# flc_reva_me14 register map
Registers are access not given, no defined reset value unless marked. A register's access mark holds for its fields unless they carry their own. Offsets are from the block's base; lines under a group give offsets from that group; [hi:lo] are bit positions; {n}, {i} and the like mark numbered series; 'fields as' and 'values as' point back to an identical list; <NAME> marks a mode.

## Memory map
0x40029000 FLC size 0x1000 — Flash Memory Control.

## Interrupts
23 Flash_Controller (FLC) — Flash Controller interrupt.

## FLC — Flash Memory Control.
Base 0x40029000; register names take the prefix FLSH_
0x00 ADDR — Flash Write Address.
  [31:0] ADDR — Address for next operation.
0x04 CLKDIV reset 0x64 — Flash Clock Divide. The clock (PLL0) is divided by this value to generate a 1 MHz clock for Flash controller.
  [7:0] CLKDIV — Flash Clock Divide. The clock is divided by this value to generate a 1MHz clock for flash controller.
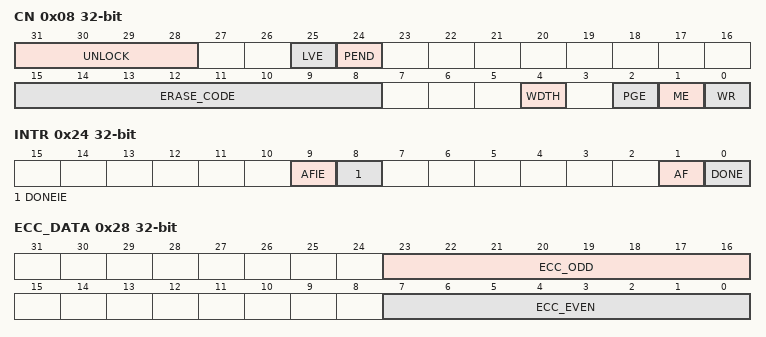
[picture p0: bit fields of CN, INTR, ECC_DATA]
0x08 CN — Flash Control Register.
  [31:28] UNLOCK — Flash Unlock. The correct unlock code must be written to these four bits before any Flash write or erase operation is allowed.
    2=unlocked (Flash Unlocked.); 3=locked (Flash Locked.)
  [25] LVE ro — Low Voltage Read Enable
    0=dis (Disabled.); 1=en (Enabled.)
  [24] PEND ro — Flash Pending. When Flash operation is in progress (busy), Flash reads and writes will fail. When PEND is set, write to all Flash registers, with exception of the Flash interrupt register, are ignored.
    0=idle; 1=busy
  [15:8] ERASE_CODE — Erase Code. The ERASE_CODE must be set up property before erase operation can be initiated. These bits are automatically cleared after the operation is complete.
    0=nop (No operation.); 85=erasePage (Enable Page Erase.); 170=eraseAll (Enable Mass Erase. The debug port must be enabled.)
  [4] WDTH — Data Width. This bits selects write data width.
    0=size128 (128-bit.); 1=size32 (32-bit.)
  [2] PGE — Page Erase. This bit is automatically cleared after the operation.
    0=complete (No operation/complete.); 1=Start operation
  [1] ME — Mass Erase. This bit is automatically cleared after the operation.
    0=complete (No operation/complete.); 1=Start operation
  [0] WR — Write. This bit is automatically cleared after the operation.
    0=complete (No operation/complete.); 1=Start operation
0x24 INTR — Flash Interrupt Register.
  [9] AFIE — Flash Done Interrupt Enable.
    0=disable; 1=enable
  [8] DONEIE — Flash Done Interrupt Enable.
    0=disable; 1=enable
  [1] AF — Flash Access Fail. This bit is set when an attempt is made to write the flash while the flash is busy or the flash is locked. This bit can only be set to 1 by hardware.
    0=noError (No Failure.); 1=error (Failure occurs.)
  [0] DONE — Flash Done Interrupt. This bit is set to 1 upon Flash write or erase completion.
    0=inactive (No interrupt is pending.); 1=pending (An interrupt is pending.)
0x28 ECC_DATA ro — Flash Controller ECC Data Register.
  [23:16] ECC_ODD — Error Correction Code Odd Data.
  [7:0] ECC_EVEN — Error Correction Code Even Data.
{0x30+4i} DATA[{i}] (i=0..3) — Flash Write Data.
  [31:0] DATA — Data next operation.
0x40 ACTNL wo — Access Control Register. Writing the ACNTL register with the following values in the order shown, allows read and write access to the system and user Information block: pflc-acntl = 0x3a7f5ca3; pflc-acntl = 0xa1e34f20; pflc-acntl = 0x9608b2c1. When unlocked, a write of any word will disable access to system and user information block. Readback of this register is always zero.
  [31:0] ACNTL — Access control.
